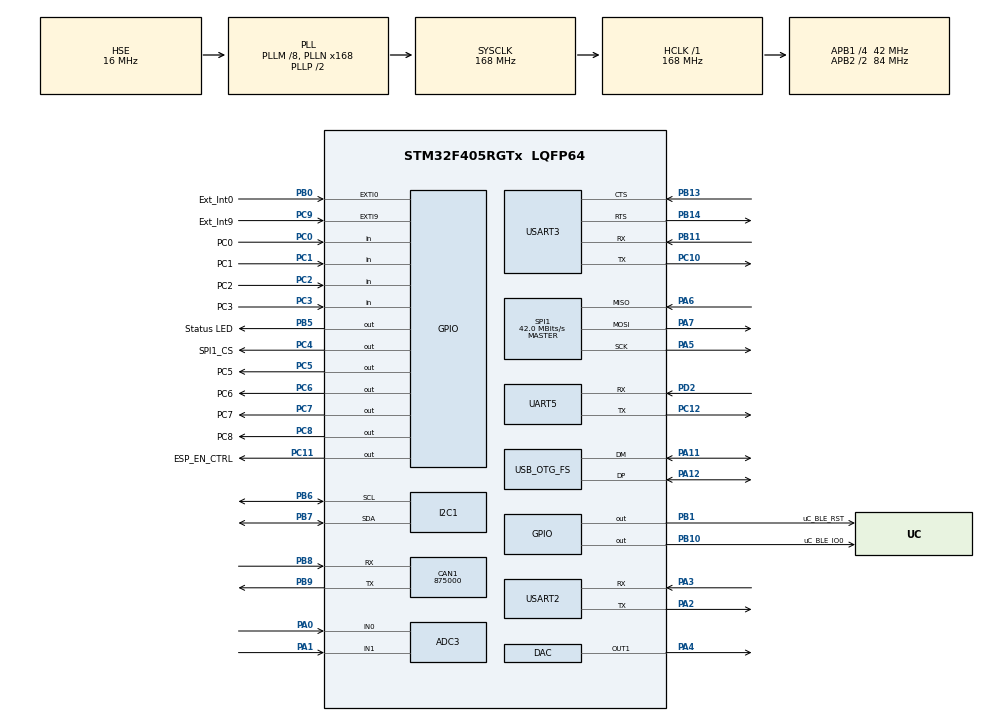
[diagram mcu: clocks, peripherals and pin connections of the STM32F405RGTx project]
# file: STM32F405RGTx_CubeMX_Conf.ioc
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Mcu.Family=STM32F4
PA6.Mode=Full_Duplex_Master
USB_DEVICE.CLASS_NAME_FS=CDC
PH0-OSC_IN.Signal=RCC_OSC_IN
VP_SYS_VS_tim6.Mode=TIM6
RCC.CortexFreq_Value=168000000
SPI1.VirtualType=VM_MASTER
NVIC.TIM6_DAC_IRQn=true\:0\:0\:false\:false\:true\:false\:false\:true
PC12.Signal=UART5_TX
PC10.Signal=USART3_TX
PC0.GPIO_Label=PC0
PC6.GPIO_Label=PC6
VP_RTC_VS_RTC_Activate.Mode=RTC_Enabled
PA11.Mode=Device_Only
PB0.GPIO_Label=Ext_Int0
USB_DEVICE.VirtualMode-CDC_FS=Cdc
PB11.Signal=USART3_RX
PB13.Signal=USART3_CTS
ADC3.Channel-0\#ChannelRegularConversion=ADC_CHANNEL_0
RCC.SYSCLKSource=RCC_SYSCLKSOURCE_PLLCLK
ProjectManager.StackSize=0x400
PA12.Signal=USB_OTG_FS_DP
SPI1.Direction=SPI_DIRECTION_2LINES
RCC.HCLKFreq_Value=168000000
RCC.APB2TimFreq_Value=168000000
PB6.Signal=I2C1_SCL
PC7.Signal=GPIO_Output
PB6.Mode=SMBus-two-wire-Interface
SPI1.CalculateBaudRate=42.0 MBits/s
PC3.Signal=GPIO_Input
RCC.AHBFreq_Value=168000000
PH0-OSC_IN.Mode=HSE-External-Oscillator
RCC.HSE_VALUE=16000000
PB3.Mode=Trace_Asynchronous_SW
PC4.GPIO_Label=SPI1_CS
PA14.Mode=Trace_Asynchronous_SW
PB14.Mode=CTS_RTS
PB1.GPIO_Label=uC_BLE_RST
PC11.GPIO_Label=ESP_EN_CTRL
PB7.Signal=I2C1_SDA
SH.ADCx_IN0.0=ADC3_IN0,IN0
VP_FREERTOS_VS_CMSIS_V1.Mode=CMSIS_V1
PH1-OSC_OUT.Mode=HSE-External-Oscillator
Mcu.Package=LQFP64
PB9.Signal=CAN1_TX
PB1.Signal=GPIO_Output
PA6.Signal=SPI1_MISO
NVIC.TimeBase=TIM6_DAC_IRQn
USART2.VirtualMode=VM_ASYNC
NVIC.OTG_FS_IRQn=true\:5\:0\:false\:false\:true\:true\:false\:true
ADC3.Rank-0\#ChannelRegularConversion=1
NVIC.TimeBaseIP=TIM6
VP_RTC_VS_RTC_Calendar.Mode=RTC_Calendar
USB_OTG_FS.VirtualMode=Device_Only
RCC.APB2CLKDivider=RCC_HCLK_DIV2
SH.ADCx_IN1.0=ADC3_IN1,IN1
PB5.GPIO_Label=Status LED
RCC.APB1TimFreq_Value=84000000
PC5.Signal=GPIO_Output
PB13.Mode=CTS_RTS
CAN1.CalculateTimeBit=1142.85
PC2.GPIO_Label=PC2
PA3.Signal=USART2_RX
CAN1.CalculateTimeQuantum=380.95238095238096
PA5.Mode=Full_Duplex_Master
SH.COMP_DAC1_group.0=DAC_OUT1,DAC_OUT1
FREERTOS.Tasks01=StatusBlinkerTa,0,128,StatusBlinkerTask_Init,Default,NULL,Dynamic,NULL,NULL
PA7.Mode=Full_Duplex_Master
PC9.GPIO_Label=Ext_Int9
USB_DEVICE.VirtualModeFS=Cdc_FS
PC11.Signal=GPIO_Output
CAN1.CalculateBaudRate=875000
PC8.Signal=GPIO_Output
PC2.Signal=GPIO_Input
PC4.Signal=GPIO_Output
PC6.Signal=GPIO_Output
PC10.Mode=Asynchronous
UART5.VirtualMode=Asynchronous
PC0.Signal=GPIO_Input
RCC.APB1CLKDivider=RCC_HCLK_DIV4
PA0-WKUP.Signal=ADCx_IN0
PC8.GPIO_Label=PC8
PA3.Mode=Asynchronous
PA13.Signal=SYS_JTMS-SWDIO
ADC3.SamplingTime-0\#ChannelRegularConversion=ADC_SAMPLETIME_3CYCLES
PB11.Mode=Asynchronous
ProjectManager.TargetToolchain=STM32CubeIDE
PB10.GPIO_Label=uC_BLE_IO0
VP_USB_DEVICE_VS_USB_DEVICE_CDC_FS.Mode=CDC_FS
PB9.Mode=CAN_Activate
RCC.LSE_VALUE=32768
PA1.Signal=ADCx_IN1
PB10.Signal=GPIO_Output
PB14.Signal=USART3_RTS
PD2.Mode=Asynchronous
PA5.Signal=SPI1_SCK
PC12.Mode=Asynchronous
board=custom
RCC.VCOOutputFreq_Value=336000000
RCC.APB2Freq_Value=84000000
SPI1.Mode=SPI_MODE_MASTER
PC1.GPIO_Label=PC1
PH1-OSC_OUT.Signal=RCC_OSC_OUT
PA13.Mode=Trace_Asynchronous_SW
Mcu.Name=STM32F405RGTx
PA2.Signal=USART2_TX
PC7.GPIO_Label=PC7
RCC.48MHZClocksFreq_Value=48000000
PB3.Signal=SYS_JTDO-SWO
PA4.Signal=COMP_DAC1_group
RCC.SYSCLKFreq_VALUE=168000000
PB5.Signal=GPIO_Output
PA12.Mode=Device_Only
PC5.GPIO_Label=PC5
USART3.VirtualMode=VM_ASYNC
PA11.Signal=USB_OTG_FS_DM
PB7.Mode=SMBus-two-wire-Interface
PA14.Signal=SYS_JTCK-SWCLK
ProjectManager.HeapSize=0x200
RCC.HSI_VALUE=16000000
RCC.PLLQ=7
NVIC.PriorityGroup=NVIC_PRIORITYGROUP_4
RCC.PLLM=8
PB8.Mode=CAN_Activate
RCC.PLLN=168
PA2.Mode=Asynchronous
PB8.Signal=CAN1_RX
PC3.GPIO_Label=PC3
PC9.Signal=GPXTI9
PD2.Signal=UART5_RX
RCC.APB1Freq_Value=42000000
ADC3.NbrOfConversionFlag=1
PB0.Signal=GPXTI0
PC1.Signal=GPIO_Input
PA7.Signal=SPI1_MOSI

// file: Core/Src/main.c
/* USER CODE BEGIN Header */
/**
  ******************************************************************************
  * @file           : main.c
  * @brief          : Main program body
  ******************************************************************************
  * @attention
  *
  * <h2><center>&copy; Copyright (c) 2021 STMicroelectronics.
  * All rights reserved.</center></h2>
  *
  * This software component is licensed by ST under Ultimate Liberty license
  * SLA0044, the "License"; You may not use this file except in compliance with
  * the License. You may obtain a copy of the License at:
  *                             www.st.com/SLA0044
  *
  ******************************************************************************
  */
/* USER CODE END Header */
#include "main.h"
#include "cmsis_os.h"
#include "usb_device.h"

ADC_HandleTypeDef hadc3;

CAN_HandleTypeDef hcan1;

DAC_HandleTypeDef hdac;

SMBUS_HandleTypeDef hsmbus1;

RTC_HandleTypeDef hrtc;

SPI_HandleTypeDef hspi1;

UART_HandleTypeDef huart5;
UART_HandleTypeDef huart2;
UART_HandleTypeDef huart3;

osThreadId StatusBlinkerTaHandle;

void SystemClock_Config(void);
static void MX_GPIO_Init(void);
static void MX_ADC3_Init(void);
static void MX_CAN1_Init(void);
static void MX_DAC_Init(void);
static void MX_I2C1_SMBUS_Init(void);
static void MX_RTC_Init(void);
static void MX_SPI1_Init(void);
static void MX_UART5_Init(void);
static void MX_USART3_UART_Init(void);
static void MX_USART2_UART_Init(void);
void StatusBlinkerTask_Init(void const * argument);

int main(void)
{

  /* MCU Configuration--------------------------------------------------------*/

  /* Reset of all peripherals, Initializes the Flash interface and the Systick. */
  HAL_Init();

  /* Configure the system clock */
  SystemClock_Config();

  /* Initialize all configured peripherals */
  MX_GPIO_Init();
  MX_ADC3_Init();
  MX_CAN1_Init();
  MX_DAC_Init();
  MX_I2C1_SMBUS_Init();
  MX_RTC_Init();
  MX_SPI1_Init();
  MX_UART5_Init();
  MX_USART3_UART_Init();
  MX_USART2_UART_Init();

  /* Create the thread(s) */
  /* definition and creation of StatusBlinkerTa */
  osThreadDef(StatusBlinkerTa, StatusBlinkerTask_Init, osPriorityNormal, 0, 128);
  StatusBlinkerTaHandle = osThreadCreate(osThread(StatusBlinkerTa), NULL);

  /* Start scheduler */
  osKernelStart();

  /* We should never get here as control is now taken by the scheduler */
  /* Infinite loop */
  while (1)
  {

  }
}

void SystemClock_Config(void)
{
  RCC_OscInitTypeDef RCC_OscInitStruct = {0};
  RCC_ClkInitTypeDef RCC_ClkInitStruct = {0};
  RCC_PeriphCLKInitTypeDef PeriphClkInitStruct = {0};

  /** Configure the main internal regulator output voltage
  */
  __HAL_RCC_PWR_CLK_ENABLE();
  __HAL_PWR_VOLTAGESCALING_CONFIG(PWR_REGULATOR_VOLTAGE_SCALE1);
  /** Initializes the RCC Oscillators according to the specified parameters
  * in the RCC_OscInitTypeDef structure.
  */
  RCC_OscInitStruct.OscillatorType = RCC_OSCILLATORTYPE_LSI|RCC_OSCILLATORTYPE_HSE;
  RCC_OscInitStruct.HSEState = RCC_HSE_ON;
  RCC_OscInitStruct.LSIState = RCC_LSI_ON;
  RCC_OscInitStruct.PLL.PLLState = RCC_PLL_ON;
  RCC_OscInitStruct.PLL.PLLSource = RCC_PLLSOURCE_HSE;
  RCC_OscInitStruct.PLL.PLLM = 8;
  RCC_OscInitStruct.PLL.PLLN = 168;
  RCC_OscInitStruct.PLL.PLLP = RCC_PLLP_DIV2;
  RCC_OscInitStruct.PLL.PLLQ = 7;
  if (HAL_RCC_OscConfig(&RCC_OscInitStruct) != HAL_OK)
  {
    Error_Handler();
  }
  /** Initializes the CPU, AHB and APB buses clocks
  */
  RCC_ClkInitStruct.ClockType = RCC_CLOCKTYPE_HCLK|RCC_CLOCKTYPE_SYSCLK
                              |RCC_CLOCKTYPE_PCLK1|RCC_CLOCKTYPE_PCLK2;
  RCC_ClkInitStruct.SYSCLKSource = RCC_SYSCLKSOURCE_PLLCLK;
  RCC_ClkInitStruct.AHBCLKDivider = RCC_SYSCLK_DIV1;
  RCC_ClkInitStruct.APB1CLKDivider = RCC_HCLK_DIV4;
  RCC_ClkInitStruct.APB2CLKDivider = RCC_HCLK_DIV2;

  if (HAL_RCC_ClockConfig(&RCC_ClkInitStruct, FLASH_LATENCY_5) != HAL_OK)
  {
    Error_Handler();
  }
  PeriphClkInitStruct.PeriphClockSelection = RCC_PERIPHCLK_RTC;
  PeriphClkInitStruct.RTCClockSelection = RCC_RTCCLKSOURCE_LSI;
  if (HAL_RCCEx_PeriphCLKConfig(&PeriphClkInitStruct) != HAL_OK)
  {
    Error_Handler();
  }
}

static void MX_ADC3_Init(void)
{

  ADC_ChannelConfTypeDef sConfig = {0};

  /** Configure the global features of the ADC (Clock, Resolution, Data Alignment and number of conversion)
  */
  hadc3.Instance = ADC3;
  hadc3.Init.ClockPrescaler = ADC_CLOCK_SYNC_PCLK_DIV4;
  hadc3.Init.Resolution = ADC_RESOLUTION_12B;
  hadc3.Init.ScanConvMode = DISABLE;
  hadc3.Init.ContinuousConvMode = DISABLE;
  hadc3.Init.DiscontinuousConvMode = DISABLE;
  hadc3.Init.ExternalTrigConvEdge = ADC_EXTERNALTRIGCONVEDGE_NONE;
  hadc3.Init.ExternalTrigConv = ADC_SOFTWARE_START;
  hadc3.Init.DataAlign = ADC_DATAALIGN_RIGHT;
  hadc3.Init.NbrOfConversion = 1;
  hadc3.Init.DMAContinuousRequests = DISABLE;
  hadc3.Init.EOCSelection = ADC_EOC_SINGLE_CONV;
  if (HAL_ADC_Init(&hadc3) != HAL_OK)
  {
    Error_Handler();
  }
  /** Configure for the selected ADC regular channel its corresponding rank in the sequencer and its sample time.
  */
  sConfig.Channel = ADC_CHANNEL_0;
  sConfig.Rank = 1;
  sConfig.SamplingTime = ADC_SAMPLETIME_3CYCLES;
  if (HAL_ADC_ConfigChannel(&hadc3, &sConfig) != HAL_OK)
  {
    Error_Handler();
  }

}

static void MX_CAN1_Init(void)
{

  hcan1.Instance = CAN1;
  hcan1.Init.Prescaler = 16;
  hcan1.Init.Mode = CAN_MODE_NORMAL;
  hcan1.Init.SyncJumpWidth = CAN_SJW_1TQ;
  hcan1.Init.TimeSeg1 = CAN_BS1_1TQ;
  hcan1.Init.TimeSeg2 = CAN_BS2_1TQ;
  hcan1.Init.TimeTriggeredMode = DISABLE;
  hcan1.Init.AutoBusOff = DISABLE;
  hcan1.Init.AutoWakeUp = DISABLE;
  hcan1.Init.AutoRetransmission = DISABLE;
  hcan1.Init.ReceiveFifoLocked = DISABLE;
  hcan1.Init.TransmitFifoPriority = DISABLE;
  if (HAL_CAN_Init(&hcan1) != HAL_OK)
  {
    Error_Handler();
  }

}

static void MX_DAC_Init(void)
{

  DAC_ChannelConfTypeDef sConfig = {0};

  /** DAC Initialization
  */
  hdac.Instance = DAC;
  if (HAL_DAC_Init(&hdac) != HAL_OK)
  {
    Error_Handler();
  }
  /** DAC channel OUT1 config
  */
  sConfig.DAC_Trigger = DAC_TRIGGER_NONE;
  sConfig.DAC_OutputBuffer = DAC_OUTPUTBUFFER_ENABLE;
  if (HAL_DAC_ConfigChannel(&hdac, &sConfig, DAC_CHANNEL_1) != HAL_OK)
  {
    Error_Handler();
  }

}

static void MX_I2C1_SMBUS_Init(void)
{

  hsmbus1.Instance = I2C1;
  hsmbus1.Init.OwnAddress1 = 0;
  hsmbus1.Init.AddressingMode = SMBUS_ADDRESSINGMODE_7BIT;
  hsmbus1.Init.DualAddressMode = SMBUS_DUALADDRESS_DISABLE;
  hsmbus1.Init.OwnAddress2 = 0;
  hsmbus1.Init.GeneralCallMode = SMBUS_GENERALCALL_DISABLE;
  hsmbus1.Init.NoStretchMode = SMBUS_NOSTRETCH_DISABLE;
  hsmbus1.Init.PacketErrorCheckMode = SMBUS_PEC_DISABLE;
  hsmbus1.Init.PeripheralMode = SMBUS_PERIPHERAL_MODE_SMBUS_SLAVE;
  if (HAL_SMBUS_Init(&hsmbus1) != HAL_OK)
  {
    Error_Handler();
  }

}

static void MX_RTC_Init(void)
{

  RTC_TimeTypeDef sTime = {0};
  RTC_DateTypeDef sDate = {0};

  /** Initialize RTC Only
  */
  hrtc.Instance = RTC;
  hrtc.Init.HourFormat = RTC_HOURFORMAT_24;
  hrtc.Init.AsynchPrediv = 127;
  hrtc.Init.SynchPrediv = 255;
  hrtc.Init.OutPut = RTC_OUTPUT_DISABLE;
  hrtc.Init.OutPutPolarity = RTC_OUTPUT_POLARITY_HIGH;
  hrtc.Init.OutPutType = RTC_OUTPUT_TYPE_OPENDRAIN;
  if (HAL_RTC_Init(&hrtc) != HAL_OK)
  {
    Error_Handler();
  }

  /** Initialize RTC and set the Time and Date
  */
  sTime.Hours = 0x0;
  sTime.Minutes = 0x0;
  sTime.Seconds = 0x0;
  sTime.DayLightSaving = RTC_DAYLIGHTSAVING_NONE;
  sTime.StoreOperation = RTC_STOREOPERATION_RESET;
  if (HAL_RTC_SetTime(&hrtc, &sTime, RTC_FORMAT_BCD) != HAL_OK)
  {
    Error_Handler();
  }
  sDate.WeekDay = RTC_WEEKDAY_MONDAY;
  sDate.Month = RTC_MONTH_JANUARY;
  sDate.Date = 0x1;
  sDate.Year = 0x0;

  if (HAL_RTC_SetDate(&hrtc, &sDate, RTC_FORMAT_BCD) != HAL_OK)
  {
    Error_Handler();
  }

}

static void MX_SPI1_Init(void)
{

  /* SPI1 parameter configuration*/
  hspi1.Instance = SPI1;
  hspi1.Init.Mode = SPI_MODE_MASTER;
  hspi1.Init.Direction = SPI_DIRECTION_2LINES;
  hspi1.Init.DataSize = SPI_DATASIZE_8BIT;
  hspi1.Init.CLKPolarity = SPI_POLARITY_LOW;
  hspi1.Init.CLKPhase = SPI_PHASE_1EDGE;
  hspi1.Init.NSS = SPI_NSS_SOFT;
  hspi1.Init.BaudRatePrescaler = SPI_BAUDRATEPRESCALER_2;
  hspi1.Init.FirstBit = SPI_FIRSTBIT_MSB;
  hspi1.Init.TIMode = SPI_TIMODE_DISABLE;
  hspi1.Init.CRCCalculation = SPI_CRCCALCULATION_DISABLE;
  hspi1.Init.CRCPolynomial = 10;
  if (HAL_SPI_Init(&hspi1) != HAL_OK)
  {
    Error_Handler();
  }

}

static void MX_UART5_Init(void)
{

  huart5.Instance = UART5;
  huart5.Init.BaudRate = 115200;
  huart5.Init.WordLength = UART_WORDLENGTH_8B;
  huart5.Init.StopBits = UART_STOPBITS_1;
  huart5.Init.Parity = UART_PARITY_NONE;
  huart5.Init.Mode = UART_MODE_TX_RX;
  huart5.Init.HwFlowCtl = UART_HWCONTROL_NONE;
  huart5.Init.OverSampling = UART_OVERSAMPLING_16;
  if (HAL_UART_Init(&huart5) != HAL_OK)
  {
    Error_Handler();
  }

}

static void MX_USART2_UART_Init(void)
{

  huart2.Instance = USART2;
  huart2.Init.BaudRate = 115200;
  huart2.Init.WordLength = UART_WORDLENGTH_8B;
  huart2.Init.StopBits = UART_STOPBITS_1;
  huart2.Init.Parity = UART_PARITY_NONE;
  huart2.Init.Mode = UART_MODE_TX_RX;
  huart2.Init.HwFlowCtl = UART_HWCONTROL_NONE;
  huart2.Init.OverSampling = UART_OVERSAMPLING_16;
  if (HAL_UART_Init(&huart2) != HAL_OK)
  {
    Error_Handler();
  }

}

static void MX_USART3_UART_Init(void)
{

  huart3.Instance = USART3;
  huart3.Init.BaudRate = 115200;
  huart3.Init.WordLength = UART_WORDLENGTH_8B;
  huart3.Init.StopBits = UART_STOPBITS_1;
  huart3.Init.Parity = UART_PARITY_NONE;
  huart3.Init.Mode = UART_MODE_TX_RX;
  huart3.Init.HwFlowCtl = UART_HWCONTROL_RTS_CTS;
  huart3.Init.OverSampling = UART_OVERSAMPLING_16;
  if (HAL_UART_Init(&huart3) != HAL_OK)
  {
    Error_Handler();
  }

}

static void MX_GPIO_Init(void)
{
  GPIO_InitTypeDef GPIO_InitStruct = {0};

  /* GPIO Ports Clock Enable */
  __HAL_RCC_GPIOH_CLK_ENABLE();
  __HAL_RCC_GPIOC_CLK_ENABLE();
  __HAL_RCC_GPIOA_CLK_ENABLE();
  __HAL_RCC_GPIOB_CLK_ENABLE();
  __HAL_RCC_GPIOD_CLK_ENABLE();

  /*Configure GPIO pin Output Level */
  HAL_GPIO_WritePin(GPIOC, SPI1_CS_Pin|PC5_Pin|PC6_Pin|PC7_Pin
                          |PC8_Pin|ESP_EN_CTRL_Pin, GPIO_PIN_RESET);

  /*Configure GPIO pin Output Level */
  HAL_GPIO_WritePin(GPIOB, uC_BLE_RST_Pin|uC_BLE_IO0_Pin|Status_LED_Pin, GPIO_PIN_RESET);

  /*Configure GPIO pins : PC0_Pin PC1_Pin PC2_Pin PC3_Pin */
  GPIO_InitStruct.Pin = PC0_Pin|PC1_Pin|PC2_Pin|PC3_Pin;
  GPIO_InitStruct.Mode = GPIO_MODE_INPUT;
  GPIO_InitStruct.Pull = GPIO_NOPULL;
  HAL_GPIO_Init(GPIOC, &GPIO_InitStruct);

  /*Configure GPIO pins : SPI1_CS_Pin PC5_Pin PC6_Pin PC7_Pin
                           PC8_Pin ESP_EN_CTRL_Pin */
  GPIO_InitStruct.Pin = SPI1_CS_Pin|PC5_Pin|PC6_Pin|PC7_Pin
                          |PC8_Pin|ESP_EN_CTRL_Pin;
  GPIO_InitStruct.Mode = GPIO_MODE_OUTPUT_PP;
  GPIO_InitStruct.Pull = GPIO_NOPULL;
  GPIO_InitStruct.Speed = GPIO_SPEED_FREQ_LOW;
  HAL_GPIO_Init(GPIOC, &GPIO_InitStruct);

  /*Configure GPIO pin : Ext_Int0_Pin */
  GPIO_InitStruct.Pin = Ext_Int0_Pin;
  GPIO_InitStruct.Mode = GPIO_MODE_IT_RISING;
  GPIO_InitStruct.Pull = GPIO_NOPULL;
  HAL_GPIO_Init(Ext_Int0_GPIO_Port, &GPIO_InitStruct);

  /*Configure GPIO pins : uC_BLE_RST_Pin uC_BLE_IO0_Pin Status_LED_Pin */
  GPIO_InitStruct.Pin = uC_BLE_RST_Pin|uC_BLE_IO0_Pin|Status_LED_Pin;
  GPIO_InitStruct.Mode = GPIO_MODE_OUTPUT_PP;
  GPIO_InitStruct.Pull = GPIO_NOPULL;
  GPIO_InitStruct.Speed = GPIO_SPEED_FREQ_LOW;
  HAL_GPIO_Init(GPIOB, &GPIO_InitStruct);

  /*Configure GPIO pin : Ext_Int9_Pin */
  GPIO_InitStruct.Pin = Ext_Int9_Pin;
  GPIO_InitStruct.Mode = GPIO_MODE_IT_RISING;
  GPIO_InitStruct.Pull = GPIO_NOPULL;
  HAL_GPIO_Init(Ext_Int9_GPIO_Port, &GPIO_InitStruct);

}

void StatusBlinkerTask_Init(void const * argument)
{
  /* init code for USB_DEVICE */
  MX_USB_DEVICE_Init();
  /* USER CODE BEGIN 5 */
  /* Infinite loop */
  for(;;)
  {
	HAL_GPIO_TogglePin(Status_LED_GPIO_Port, Status_LED_Pin);
    osDelay(1000);
    HAL_GPIO_TogglePin(Status_LED_GPIO_Port, Status_LED_Pin);
    osDelay(1000);
  }
  /* USER CODE END 5 */
}

 /**
  * @brief  Period elapsed callback in non blocking mode
  * @note   This function is called  when TIM6 interrupt took place, inside
  * HAL_TIM_IRQHandler(). It makes a direct call to HAL_IncTick() to increment
  * a global variable "uwTick" used as application time base.
  * @param  htim : TIM handle
  * @retval None
  */
void HAL_TIM_PeriodElapsedCallback(TIM_HandleTypeDef *htim)
{
  if (htim->Instance == TIM6) {
    HAL_IncTick();
  }
}

void Error_Handler(void)
{
  __disable_irq();
  while (1)
  {
  }
}

/************************ (C) COPYRIGHT STMicroelectronics *****END OF FILE****/
